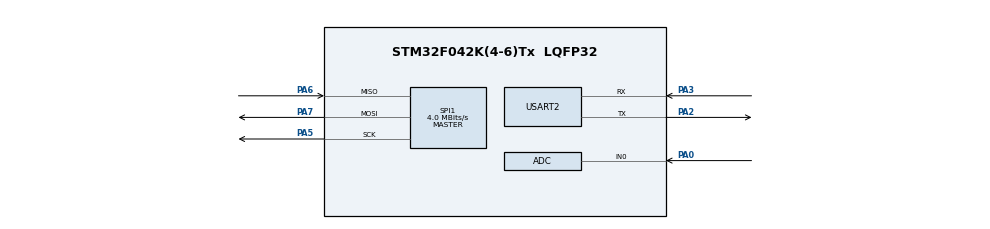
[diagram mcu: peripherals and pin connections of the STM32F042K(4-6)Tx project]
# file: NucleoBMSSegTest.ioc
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Mcu.Family=STM32F0
Mcu.Name=STM32F042K(4-6)Tx
Mcu.Package=LQFP32
PA0.Mode=IN0
PA0.Signal=ADC_IN0
PA2.Mode=Asynchronous
PA2.Signal=USART2_TX
PA3.Mode=Asynchronous
PA3.Signal=USART2_RX
PA5.Mode=Full_Duplex_Master
PA5.Signal=SPI1_SCK
PA6.Mode=Full_Duplex_Master
PA6.Signal=SPI1_MISO
PA7.Mode=Full_Duplex_Master
PA7.Signal=SPI1_MOSI
ProjectManager.HeapSize=0x200
ProjectManager.StackSize=0x400
ProjectManager.TargetToolchain=STM32CubeIDE
SPI1.CalculateBaudRate=4.0 MBits/s
SPI1.Direction=SPI_DIRECTION_2LINES
SPI1.Mode=SPI_MODE_MASTER
SPI1.VirtualType=VM_MASTER
USART2.VirtualMode-Asynchronous=VM_ASYNC
board=custom

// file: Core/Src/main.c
/* USER CODE BEGIN Header */
/**
  ******************************************************************************
  * @file           : main.c
  * @brief          : Main program body
  ******************************************************************************
  * @attention
  *
  * Copyright (c) 2022 STMicroelectronics.
  * All rights reserved.
  *
  * This software is licensed under terms that can be found in the LICENSE file
  * in the root directory of this software component.
  * If no LICENSE file comes with this software, it is provided AS-IS.
  *
  ******************************************************************************
  */
/* USER CODE END Header */
#include "main.h"

ADC_HandleTypeDef hadc;
SPI_HandleTypeDef hspi1;
UART_HandleTypeDef huart2;

void SystemClock_Config(void);
static void MX_GPIO_Init(void);
static void MX_ADC_Init(void);
static void MX_SPI1_Init(void);
static void MX_USART2_UART_Init(void);

int main(void)
{

  /* MCU Configuration--------------------------------------------------------*/

  /* Reset of all peripherals, Initializes the Flash interface and the Systick. */
  HAL_Init();

  /* Configure the system clock */
  SystemClock_Config();

  /* Initialize all configured peripherals */
  MX_GPIO_Init();
  MX_ADC_Init();
  MX_SPI1_Init();
  MX_USART2_UART_Init();
  /* USER CODE BEGIN 2 */

  uint8_t Test[] = "TODO: Configure and test MAX\r\n"; //Data to send
  HAL_UART_Transmit(&huart2,Test,sizeof(Test),10);// Sending in normal mode
  /* USER CODE END 2 */

  /* Infinite loop */
  while (1)
  {

  }
}

void SystemClock_Config(void)
{
  RCC_OscInitTypeDef RCC_OscInitStruct = {0};
  RCC_ClkInitTypeDef RCC_ClkInitStruct = {0};

  /** Initializes the RCC Oscillators according to the specified parameters
  * in the RCC_OscInitTypeDef structure.
  */
  RCC_OscInitStruct.OscillatorType = RCC_OSCILLATORTYPE_HSI|RCC_OSCILLATORTYPE_HSI14;
  RCC_OscInitStruct.HSIState = RCC_HSI_ON;
  RCC_OscInitStruct.HSI14State = RCC_HSI14_ON;
  RCC_OscInitStruct.HSICalibrationValue = RCC_HSICALIBRATION_DEFAULT;
  RCC_OscInitStruct.HSI14CalibrationValue = 16;
  RCC_OscInitStruct.PLL.PLLState = RCC_PLL_NONE;
  if (HAL_RCC_OscConfig(&RCC_OscInitStruct) != HAL_OK)
  {
    Error_Handler();
  }

  /** Initializes the CPU, AHB and APB buses clocks
  */
  RCC_ClkInitStruct.ClockType = RCC_CLOCKTYPE_HCLK|RCC_CLOCKTYPE_SYSCLK
                              |RCC_CLOCKTYPE_PCLK1;
  RCC_ClkInitStruct.SYSCLKSource = RCC_SYSCLKSOURCE_HSI;
  RCC_ClkInitStruct.AHBCLKDivider = RCC_SYSCLK_DIV1;
  RCC_ClkInitStruct.APB1CLKDivider = RCC_HCLK_DIV1;

  if (HAL_RCC_ClockConfig(&RCC_ClkInitStruct, FLASH_LATENCY_0) != HAL_OK)
  {
    Error_Handler();
  }
}

static void MX_ADC_Init(void)
{

  ADC_ChannelConfTypeDef sConfig = {0};

  /** Configure the global features of the ADC (Clock, Resolution, Data Alignment and number of conversion)
  */
  hadc.Instance = ADC1;
  hadc.Init.ClockPrescaler = ADC_CLOCK_ASYNC_DIV1;
  hadc.Init.Resolution = ADC_RESOLUTION_12B;
  hadc.Init.DataAlign = ADC_DATAALIGN_RIGHT;
  hadc.Init.ScanConvMode = ADC_SCAN_DIRECTION_FORWARD;
  hadc.Init.EOCSelection = ADC_EOC_SINGLE_CONV;
  hadc.Init.LowPowerAutoWait = DISABLE;
  hadc.Init.LowPowerAutoPowerOff = DISABLE;
  hadc.Init.ContinuousConvMode = DISABLE;
  hadc.Init.DiscontinuousConvMode = DISABLE;
  hadc.Init.ExternalTrigConv = ADC_SOFTWARE_START;
  hadc.Init.ExternalTrigConvEdge = ADC_EXTERNALTRIGCONVEDGE_NONE;
  hadc.Init.DMAContinuousRequests = DISABLE;
  hadc.Init.Overrun = ADC_OVR_DATA_PRESERVED;
  if (HAL_ADC_Init(&hadc) != HAL_OK)
  {
    Error_Handler();
  }

  /** Configure for the selected ADC regular channel to be converted.
  */
  sConfig.Channel = ADC_CHANNEL_0;
  sConfig.Rank = ADC_RANK_CHANNEL_NUMBER;
  sConfig.SamplingTime = ADC_SAMPLETIME_1CYCLE_5;
  if (HAL_ADC_ConfigChannel(&hadc, &sConfig) != HAL_OK)
  {
    Error_Handler();
  }

}

static void MX_SPI1_Init(void)
{

  /* SPI1 parameter configuration*/
  hspi1.Instance = SPI1;
  hspi1.Init.Mode = SPI_MODE_MASTER;
  hspi1.Init.Direction = SPI_DIRECTION_2LINES;
  hspi1.Init.DataSize = SPI_DATASIZE_4BIT;
  hspi1.Init.CLKPolarity = SPI_POLARITY_LOW;
  hspi1.Init.CLKPhase = SPI_PHASE_1EDGE;
  hspi1.Init.NSS = SPI_NSS_SOFT;
  hspi1.Init.BaudRatePrescaler = SPI_BAUDRATEPRESCALER_2;
  hspi1.Init.FirstBit = SPI_FIRSTBIT_MSB;
  hspi1.Init.TIMode = SPI_TIMODE_DISABLE;
  hspi1.Init.CRCCalculation = SPI_CRCCALCULATION_DISABLE;
  hspi1.Init.CRCPolynomial = 7;
  hspi1.Init.CRCLength = SPI_CRC_LENGTH_DATASIZE;
  hspi1.Init.NSSPMode = SPI_NSS_PULSE_ENABLE;
  if (HAL_SPI_Init(&hspi1) != HAL_OK)
  {
    Error_Handler();
  }

}

static void MX_USART2_UART_Init(void)
{

  huart2.Instance = USART2;
  huart2.Init.BaudRate = 38400;
  huart2.Init.WordLength = UART_WORDLENGTH_8B;
  huart2.Init.StopBits = UART_STOPBITS_1;
  huart2.Init.Parity = UART_PARITY_NONE;
  huart2.Init.Mode = UART_MODE_TX_RX;
  huart2.Init.HwFlowCtl = UART_HWCONTROL_NONE;
  huart2.Init.OverSampling = UART_OVERSAMPLING_16;
  huart2.Init.OneBitSampling = UART_ONE_BIT_SAMPLE_DISABLE;
  huart2.AdvancedInit.AdvFeatureInit = UART_ADVFEATURE_NO_INIT;
  if (HAL_UART_Init(&huart2) != HAL_OK)
  {
    Error_Handler();
  }

}

static void MX_GPIO_Init(void)
{

  /* GPIO Ports Clock Enable */
  __HAL_RCC_GPIOA_CLK_ENABLE();

}

void Error_Handler(void)
{
  __disable_irq();
  while (1)
  {
  }
}
